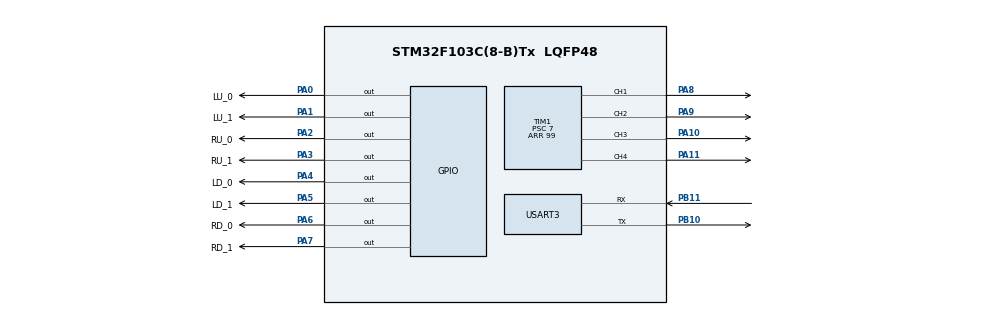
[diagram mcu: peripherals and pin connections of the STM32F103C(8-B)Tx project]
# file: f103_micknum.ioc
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Dma.Request0=USART3_RX
Dma.Request1=USART3_TX
Dma.USART3_RX.0.Direction=DMA_PERIPH_TO_MEMORY
Dma.USART3_RX.0.Instance=DMA1_Channel3
Dma.USART3_RX.0.MemDataAlignment=DMA_MDATAALIGN_BYTE
Dma.USART3_RX.0.MemInc=DMA_MINC_ENABLE
Dma.USART3_RX.0.Mode=DMA_NORMAL
Dma.USART3_RX.0.PeriphDataAlignment=DMA_PDATAALIGN_BYTE
Dma.USART3_RX.0.PeriphInc=DMA_PINC_DISABLE
Dma.USART3_RX.0.Priority=DMA_PRIORITY_LOW
Dma.USART3_TX.1.Direction=DMA_MEMORY_TO_PERIPH
Dma.USART3_TX.1.Instance=DMA1_Channel2
Dma.USART3_TX.1.MemDataAlignment=DMA_MDATAALIGN_BYTE
Dma.USART3_TX.1.MemInc=DMA_MINC_ENABLE
Dma.USART3_TX.1.Mode=DMA_NORMAL
Dma.USART3_TX.1.PeriphDataAlignment=DMA_PDATAALIGN_BYTE
Dma.USART3_TX.1.PeriphInc=DMA_PINC_DISABLE
Dma.USART3_TX.1.Priority=DMA_PRIORITY_LOW
Mcu.Family=STM32F1
Mcu.Name=STM32F103C(8-B)Tx
Mcu.Package=LQFP48
NVIC.DMA1_Channel2_IRQn=true\:0\:0\:false\:false\:true\:false\:true\:true
NVIC.DMA1_Channel3_IRQn=true\:0\:0\:false\:false\:true\:false\:true\:true
NVIC.PriorityGroup=NVIC_PRIORITYGROUP_4
NVIC.USART3_IRQn=true\:0\:0\:false\:false\:true\:true\:true\:true
PA0-WKUP.GPIO_Label=LU_0
PA0-WKUP.Signal=GPIO_Output
PA1.GPIO_Label=LU_1
PA1.Signal=GPIO_Output
PA10.Signal=S_TIM1_CH3
PA11.Signal=S_TIM1_CH4
PA13.Mode=Serial_Wire
PA13.Signal=SYS_JTMS-SWDIO
PA14.Mode=Serial_Wire
PA14.Signal=SYS_JTCK-SWCLK
PA2.GPIO_Label=RU_0
PA2.Signal=GPIO_Output
PA3.GPIO_Label=RU_1
PA3.Signal=GPIO_Output
PA4.GPIO_Label=LD_0
PA4.Signal=GPIO_Output
PA5.GPIO_Label=LD_1
PA5.Signal=GPIO_Output
PA6.GPIO_Label=RD_0
PA6.Signal=GPIO_Output
PA7.GPIO_Label=RD_1
PA7.Signal=GPIO_Output
PA8.Signal=S_TIM1_CH1
PA9.Signal=S_TIM1_CH2
PB10.Mode=Asynchronous
PB10.Signal=USART3_TX
PB11.Mode=Asynchronous
PB11.Signal=USART3_RX
ProjectManager.HeapSize=0x200
ProjectManager.StackSize=0x400
ProjectManager.TargetToolchain=CMake
RCC.APB1Freq_Value=8000000
RCC.APB2Freq_Value=8000000
SH.S_TIM1_CH1.0=TIM1_CH1,PWM Generation1 CH1
SH.S_TIM1_CH2.0=TIM1_CH2,PWM Generation2 CH2
SH.S_TIM1_CH3.0=TIM1_CH3,PWM Generation3 CH3
SH.S_TIM1_CH4.0=TIM1_CH4,PWM Generation4 CH4
TIM1.Channel-PWM\ Generation1\ CH1=TIM_CHANNEL_1
TIM1.Channel-PWM\ Generation2\ CH2=TIM_CHANNEL_2
TIM1.Channel-PWM\ Generation3\ CH3=TIM_CHANNEL_3
TIM1.Channel-PWM\ Generation4\ CH4=TIM_CHANNEL_4
TIM1.Period=99
TIM1.Prescaler=7
USART3.VirtualMode=VM_ASYNC
VP_TIM1_VS_ClockSourceINT.Mode=Internal
board=custom

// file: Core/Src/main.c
/* USER CODE BEGIN Header */
/**
  ******************************************************************************
  * @file           : main.c
  * @brief          : Main program body
  ******************************************************************************
  * @attention
  *
  * Copyright (c) 2026 STMicroelectronics.
  * All rights reserved.
  *
  * This software is licensed under terms that can be found in the LICENSE file
  * in the root directory of this software component.
  * If no LICENSE file comes with this software, it is provided AS-IS.
  *
  ******************************************************************************
  */
/* USER CODE END Header */
#include "main.h"

/* USER CODE BEGIN Includes */
#include <string.h>
#include <stdio.h>
#include "ps2_hal.h"
#include "micnum.h"
/* USER CODE END Includes */

TIM_HandleTypeDef htim1;

UART_HandleTypeDef huart3;
DMA_HandleTypeDef hdma_usart3_rx;
DMA_HandleTypeDef hdma_usart3_tx;

/* USER CODE BEGIN PV */
PS2_TypeDef ps2_data;  // PS2手柄数据结构体
char uart_buffer[200]; // 串口发送缓冲区
/* USER CODE END PV */

void SystemClock_Config(void);
static void MX_GPIO_Init(void);
static void MX_DMA_Init(void);
static void MX_TIM1_Init(void);
static void MX_USART3_UART_Init(void);

int main(void)
{

  /* MCU Configuration--------------------------------------------------------*/

  /* Reset of all peripherals, Initializes the Flash interface and the Systick. */
  HAL_Init();

  /* Configure the system clock */
  SystemClock_Config();

  /* Initialize all configured peripherals */
  MX_GPIO_Init();
  MX_DMA_Init();
  MX_TIM1_Init();
  MX_USART3_UART_Init();
  /* USER CODE BEGIN 2 */
  HAL_TIM_PWM_Start(&htim1, TIM_CHANNEL_1);
  HAL_TIM_PWM_Start(&htim1, TIM_CHANNEL_2);
  HAL_TIM_PWM_Start(&htim1, TIM_CHANNEL_3);
  HAL_TIM_PWM_Start(&htim1, TIM_CHANNEL_4);

  PS2_Init(); // 初始化PS2手柄
  HAL_Delay(100); // 延时100ms，等待手柄稳定

  /* USER CODE END 2 */

  /* Infinite loop */
  while (1)
  {

    // 读取PS2手柄数据
    PS2_ScanKey(&ps2_data);

    // 格式化输出摇杆数据
    sprintf(uart_buffer, "Mode:0x%02X Btn1:0x%02X Btn2:0x%02X | RJoy_LR:%3d RJoy_UD:%3d | LJoy_LR:%3d LJoy_UD:%3d\r\n",
            ps2_data.mode,
            ps2_data.btn1,
            ps2_data.btn2,
            ps2_data.RJoy_LR,
            ps2_data.RJoy_UD,
            ps2_data.LJoy_LR,
            ps2_data.LJoy_UD);

    // 左摇杆控制平移（前后+左右）
    // PS2摇杆中心值约为128，范围0-255
    int vx = (127 - ps2_data.LJoy_UD) * 50 / 127; // 前后速度：-100到100
    int vy = (128 - ps2_data.LJoy_LR) * 50 / 128; // 左右速度：-100到100

    // 右摇杆控制旋转
    int wz = (128 - ps2_data.RJoy_LR) * 50 / 128; // 旋转速度：-100到100

    // 死区处理，避免摇杆漂移
    if(vx > -10 && vx < 10) vx = 0;
    if(vy > -10 && vy < 10) vy = 0;
    if(wz > -10 && wz < 10) wz = 0;

    // 麦轮运动学计算每个轮子的速度
    // 对于标准麦轮配置（X型布局）：
    int speed_LU = vx - vy - wz;  // 左上轮
    int speed_RU = vx + vy + wz;  // 右上轮
    int speed_LD = vx + vy - wz;  // 左下轮
    int speed_RD = vx - vy + wz;  // 右下轮

    // 速度归一化，防止超出范围
    int max_speed = speed_LU;
    if(speed_RU > max_speed || speed_RU < -max_speed) max_speed = (speed_RU > 0) ? speed_RU : -speed_RU;
    if(speed_LD > max_speed || speed_LD < -max_speed) max_speed = (speed_LD > 0) ? speed_LD : -speed_LD;
    if(speed_RD > max_speed || speed_RD < -max_speed) max_speed = (speed_RD > 0) ? speed_RD : -speed_RD;

    if(max_speed > 100)
    {
      speed_LU = speed_LU * 100 / max_speed;
      speed_RU = speed_RU * 100 / max_speed;
      speed_LD = speed_LD * 100 / max_speed;
      speed_RD = speed_RD * 100 / max_speed;
    }

    // 设置各个电机的速度和方向
    Set_Motor_Speed(1, speed_LU);
    Set_Motor_Speed(2, speed_RU);
    Set_Motor_Speed(3, speed_LD);
    Set_Motor_Speed(4, speed_RD);

    // 通过串口发送数据
    HAL_UART_Transmit(&huart3, (uint8_t*)uart_buffer, strlen(uart_buffer), HAL_MAX_DELAY);

    HAL_Delay(100);  // 100ms刷新一次
  }
}

void SystemClock_Config(void)
{
  RCC_OscInitTypeDef RCC_OscInitStruct = {0};
  RCC_ClkInitTypeDef RCC_ClkInitStruct = {0};

  /** Initializes the RCC Oscillators according to the specified parameters
  * in the RCC_OscInitTypeDef structure.
  */
  RCC_OscInitStruct.OscillatorType = RCC_OSCILLATORTYPE_HSI;
  RCC_OscInitStruct.HSIState = RCC_HSI_ON;
  RCC_OscInitStruct.HSICalibrationValue = RCC_HSICALIBRATION_DEFAULT;
  RCC_OscInitStruct.PLL.PLLState = RCC_PLL_NONE;
  if (HAL_RCC_OscConfig(&RCC_OscInitStruct) != HAL_OK)
  {
    Error_Handler();
  }

  /** Initializes the CPU, AHB and APB buses clocks
  */
  RCC_ClkInitStruct.ClockType = RCC_CLOCKTYPE_HCLK|RCC_CLOCKTYPE_SYSCLK
                              |RCC_CLOCKTYPE_PCLK1|RCC_CLOCKTYPE_PCLK2;
  RCC_ClkInitStruct.SYSCLKSource = RCC_SYSCLKSOURCE_HSI;
  RCC_ClkInitStruct.AHBCLKDivider = RCC_SYSCLK_DIV1;
  RCC_ClkInitStruct.APB1CLKDivider = RCC_HCLK_DIV1;
  RCC_ClkInitStruct.APB2CLKDivider = RCC_HCLK_DIV1;

  if (HAL_RCC_ClockConfig(&RCC_ClkInitStruct, FLASH_LATENCY_0) != HAL_OK)
  {
    Error_Handler();
  }
}

static void MX_TIM1_Init(void)
{

  TIM_ClockConfigTypeDef sClockSourceConfig = {0};
  TIM_MasterConfigTypeDef sMasterConfig = {0};
  TIM_OC_InitTypeDef sConfigOC = {0};
  TIM_BreakDeadTimeConfigTypeDef sBreakDeadTimeConfig = {0};

  htim1.Instance = TIM1;
  htim1.Init.Prescaler = 7;
  htim1.Init.CounterMode = TIM_COUNTERMODE_UP;
  htim1.Init.Period = 99;
  htim1.Init.ClockDivision = TIM_CLOCKDIVISION_DIV1;
  htim1.Init.RepetitionCounter = 0;
  htim1.Init.AutoReloadPreload = TIM_AUTORELOAD_PRELOAD_DISABLE;
  if (HAL_TIM_Base_Init(&htim1) != HAL_OK)
  {
    Error_Handler();
  }
  sClockSourceConfig.ClockSource = TIM_CLOCKSOURCE_INTERNAL;
  if (HAL_TIM_ConfigClockSource(&htim1, &sClockSourceConfig) != HAL_OK)
  {
    Error_Handler();
  }
  if (HAL_TIM_PWM_Init(&htim1) != HAL_OK)
  {
    Error_Handler();
  }
  sMasterConfig.MasterOutputTrigger = TIM_TRGO_RESET;
  sMasterConfig.MasterSlaveMode = TIM_MASTERSLAVEMODE_DISABLE;
  if (HAL_TIMEx_MasterConfigSynchronization(&htim1, &sMasterConfig) != HAL_OK)
  {
    Error_Handler();
  }
  sConfigOC.OCMode = TIM_OCMODE_PWM1;
  sConfigOC.Pulse = 0;
  sConfigOC.OCPolarity = TIM_OCPOLARITY_HIGH;
  sConfigOC.OCNPolarity = TIM_OCNPOLARITY_HIGH;
  sConfigOC.OCFastMode = TIM_OCFAST_DISABLE;
  sConfigOC.OCIdleState = TIM_OCIDLESTATE_RESET;
  sConfigOC.OCNIdleState = TIM_OCNIDLESTATE_RESET;
  if (HAL_TIM_PWM_ConfigChannel(&htim1, &sConfigOC, TIM_CHANNEL_1) != HAL_OK)
  {
    Error_Handler();
  }
  if (HAL_TIM_PWM_ConfigChannel(&htim1, &sConfigOC, TIM_CHANNEL_2) != HAL_OK)
  {
    Error_Handler();
  }
  if (HAL_TIM_PWM_ConfigChannel(&htim1, &sConfigOC, TIM_CHANNEL_3) != HAL_OK)
  {
    Error_Handler();
  }
  if (HAL_TIM_PWM_ConfigChannel(&htim1, &sConfigOC, TIM_CHANNEL_4) != HAL_OK)
  {
    Error_Handler();
  }
  sBreakDeadTimeConfig.OffStateRunMode = TIM_OSSR_DISABLE;
  sBreakDeadTimeConfig.OffStateIDLEMode = TIM_OSSI_DISABLE;
  sBreakDeadTimeConfig.LockLevel = TIM_LOCKLEVEL_OFF;
  sBreakDeadTimeConfig.DeadTime = 0;
  sBreakDeadTimeConfig.BreakState = TIM_BREAK_DISABLE;
  sBreakDeadTimeConfig.BreakPolarity = TIM_BREAKPOLARITY_HIGH;
  sBreakDeadTimeConfig.AutomaticOutput = TIM_AUTOMATICOUTPUT_DISABLE;
  if (HAL_TIMEx_ConfigBreakDeadTime(&htim1, &sBreakDeadTimeConfig) != HAL_OK)
  {
    Error_Handler();
  }
  HAL_TIM_MspPostInit(&htim1);

}

static void MX_USART3_UART_Init(void)
{

  huart3.Instance = USART3;
  huart3.Init.BaudRate = 115200;
  huart3.Init.WordLength = UART_WORDLENGTH_8B;
  huart3.Init.StopBits = UART_STOPBITS_1;
  huart3.Init.Parity = UART_PARITY_NONE;
  huart3.Init.Mode = UART_MODE_TX_RX;
  huart3.Init.HwFlowCtl = UART_HWCONTROL_NONE;
  huart3.Init.OverSampling = UART_OVERSAMPLING_16;
  if (HAL_UART_Init(&huart3) != HAL_OK)
  {
    Error_Handler();
  }

}

static void MX_DMA_Init(void)
{

  /* DMA controller clock enable */
  __HAL_RCC_DMA1_CLK_ENABLE();

  /* DMA interrupt init */
  /* DMA1_Channel2_IRQn interrupt configuration */
  HAL_NVIC_SetPriority(DMA1_Channel2_IRQn, 0, 0);
  HAL_NVIC_EnableIRQ(DMA1_Channel2_IRQn);
  /* DMA1_Channel3_IRQn interrupt configuration */
  HAL_NVIC_SetPriority(DMA1_Channel3_IRQn, 0, 0);
  HAL_NVIC_EnableIRQ(DMA1_Channel3_IRQn);

}

static void MX_GPIO_Init(void)
{
  GPIO_InitTypeDef GPIO_InitStruct = {0};

  /* GPIO Ports Clock Enable */
  __HAL_RCC_GPIOA_CLK_ENABLE();
  __HAL_RCC_GPIOB_CLK_ENABLE();

  /*Configure GPIO pin Output Level */
  HAL_GPIO_WritePin(GPIOA, LU_0_Pin|LU_1_Pin|RU_0_Pin|RU_1_Pin
                          |LD_0_Pin|LD_1_Pin|RD_0_Pin|RD_1_Pin, GPIO_PIN_RESET);

  /*Configure GPIO pins : LU_0_Pin LU_1_Pin RU_0_Pin RU_1_Pin
                           LD_0_Pin LD_1_Pin RD_0_Pin RD_1_Pin */
  GPIO_InitStruct.Pin = LU_0_Pin|LU_1_Pin|RU_0_Pin|RU_1_Pin
                          |LD_0_Pin|LD_1_Pin|RD_0_Pin|RD_1_Pin;
  GPIO_InitStruct.Mode = GPIO_MODE_OUTPUT_PP;
  GPIO_InitStruct.Pull = GPIO_NOPULL;
  GPIO_InitStruct.Speed = GPIO_SPEED_FREQ_LOW;
  HAL_GPIO_Init(GPIOA, &GPIO_InitStruct);

}

void Error_Handler(void)
{
  __disable_irq();
  while (1)
  {
  }
}
